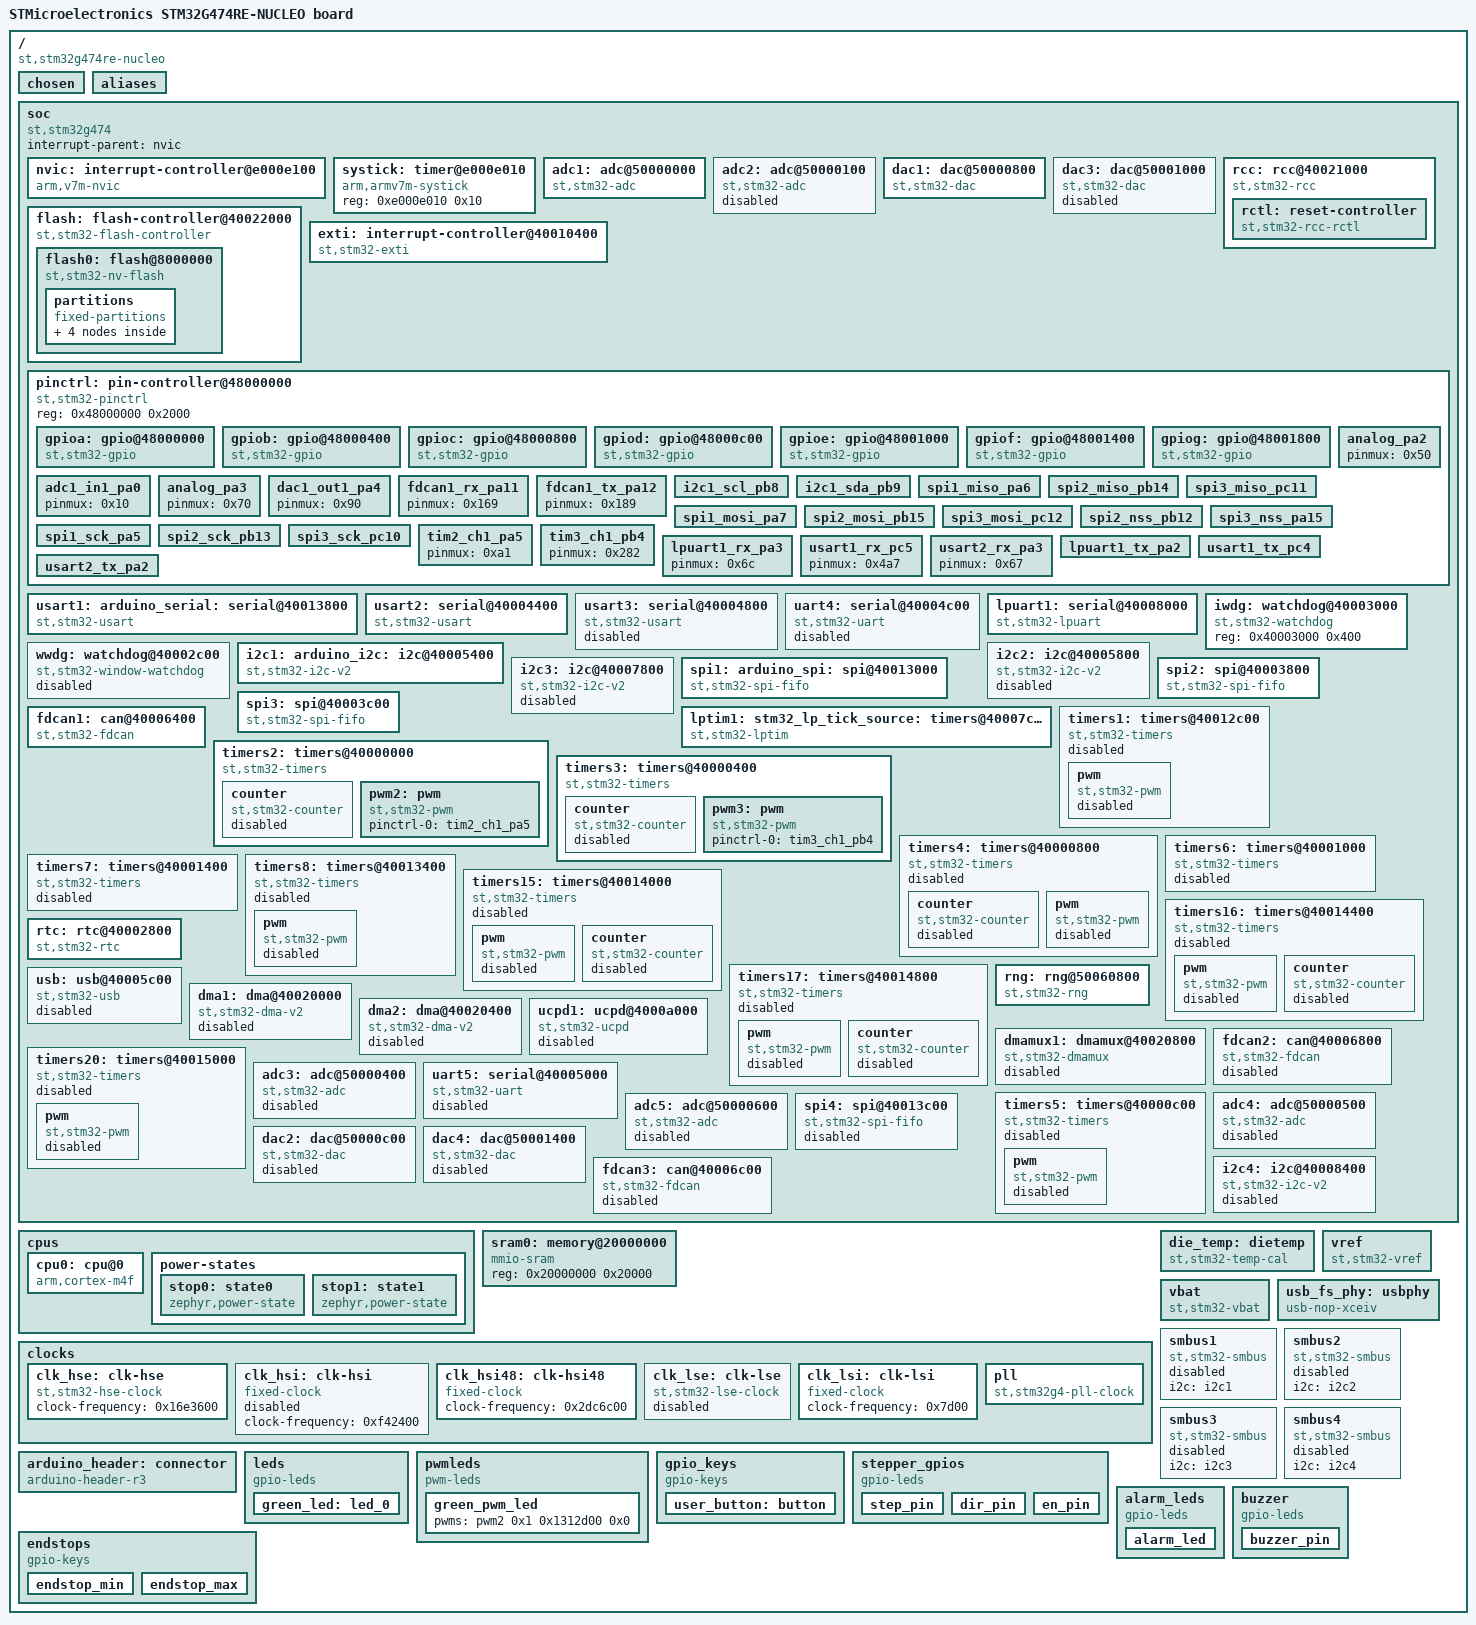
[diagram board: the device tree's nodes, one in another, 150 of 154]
/dts-v1/;

/ {
	#address-cells = < 0x1 >;
	#size-cells = < 0x1 >;
	model = "STMicroelectronics STM32G474RE-NUCLEO board";
	compatible = "st,stm32g474re-nucleo";
	chosen {
		zephyr,entropy = &rng;
		zephyr,flash-controller = &flash;
		zephyr,console = &lpuart1;
		zephyr,shell-uart = &lpuart1;
		zephyr,sram = &sram0;
		zephyr,flash = &flash0;
		zephyr,canbus = &fdcan1;
		zephyr,code-partition = &slot0_partition;
	};
	aliases {
		led0 = &green_led;
		mcuboot-led0 = &green_led;
		pwm-led0 = &green_pwm_led;
		sw0 = &user_button;
		watchdog0 = &iwdg;
		die-temp0 = &die_temp;
		volt-sensor0 = &vref;
		volt-sensor1 = &vbat;
	};
	soc {
		#address-cells = < 0x1 >;
		#size-cells = < 0x1 >;
		compatible = "st,stm32g474", "st,stm32g4", "simple-bus";
		interrupt-parent = < &nvic >;
		ranges;
		nvic: interrupt-controller@e000e100 {
			#address-cells = < 0x1 >;
			compatible = "arm,v7m-nvic";
			reg = < 0xe000e100 0xc00 >;
			interrupt-controller;
			#interrupt-cells = < 0x2 >;
			arm,num-irq-priority-bits = < 0x4 >;
			phandle = < 0x1 >;
		};
		systick: timer@e000e010 {
			compatible = "arm,armv7m-systick";
			reg = < 0xe000e010 0x10 >;
		};
		adc1: adc@50000000 {
			compatible = "st,stm32-adc";
			reg = < 0x50000000 0x100 >;
			clocks = < &rcc 0x4c 0x2000 >;
			interrupts = < 0x12 0x0 >;
			status = "okay";
			#io-channel-cells = < 0x1 >;
			resolutions = < 0x60630c 0x51630c 0x42630c 0x33630c >;
			sampling-times = < 0x3 0x7 0xd 0x19 0x30 0x5d 0xf8 0x281 >;
			st,adc-sequencer = < 0x1 >;
			pinctrl-0 = < &adc1_in1_pa0 >;
			pinctrl-names = "default";
			st,adc-clock-source = < 0x1 >;
			st,adc-prescaler = < 0x4 >;
			phandle = < 0x25 >;
		};
		adc2: adc@50000100 {
			compatible = "st,stm32-adc";
			reg = < 0x50000100 0x100 >;
			clocks = < &rcc 0x4c 0x2000 >;
			interrupts = < 0x12 0x0 >;
			status = "disabled";
			#io-channel-cells = < 0x1 >;
			resolutions = < 0x60630c 0x51630c 0x42630c 0x33630c >;
			sampling-times = < 0x3 0x7 0xd 0x19 0x30 0x5d 0xf8 0x281 >;
			st,adc-sequencer = < 0x1 >;
		};
		dac1: dac@50000800 {
			compatible = "st,stm32-dac";
			reg = < 0x50000800 0x400 >;
			clocks = < &rcc 0x4c 0x10000 >;
			status = "okay";
			#io-channel-cells = < 0x1 >;
			pinctrl-0 = < &dac1_out1_pa4 >;
			pinctrl-names = "default";
		};
		dac3: dac@50001000 {
			compatible = "st,stm32-dac";
			reg = < 0x50001000 0x400 >;
			clocks = < &rcc 0x4c 0x40000 >;
			status = "disabled";
			#io-channel-cells = < 0x1 >;
		};
		flash: flash-controller@40022000 {
			compatible = "st,stm32-flash-controller", "st,stm32g4-flash-controller";
			reg = < 0x40022000 0x400 >;
			interrupts = < 0x3 0x0 >;
			clocks = < &rcc 0x48 0x100 >;
			#address-cells = < 0x1 >;
			#size-cells = < 0x1 >;
			flash0: flash@8000000 {
				compatible = "st,stm32-nv-flash", "soc-nv-flash";
				write-block-size = < 0x8 >;
				erase-block-size = < 0x800 >;
				max-erase-time = < 0x19 >;
				reg = < 0x8000000 0x80000 >;
				partitions {
					compatible = "fixed-partitions";
					#address-cells = < 0x1 >;
					#size-cells = < 0x1 >;
					boot_partition: partition@0 {
						label = "mcuboot";
						reg = < 0x0 0x8800 >;
					};
					slot0_partition: partition@8800 {
						label = "image-0";
						reg = < 0x8800 0x3c000 >;
					};
					slot1_partition: partition@44800 {
						label = "image-1";
						reg = < 0x44800 0x3a800 >;
					};
					storage_partition: partition@7f000 {
						label = "storage";
						reg = < 0x7f000 0x1000 >;
					};
				};
			};
		};
		rcc: rcc@40021000 {
			compatible = "st,stm32-rcc";
			#clock-cells = < 0x2 >;
			reg = < 0x40021000 0x400 >;
			undershoot-prevention;
			clocks = < &pll >;
			clock-frequency = < 0xa21fe80 >;
			ahb-prescaler = < 0x1 >;
			apb1-prescaler = < 0x1 >;
			apb2-prescaler = < 0x1 >;
			phandle = < 0x2 >;
			rctl: reset-controller {
				compatible = "st,stm32-rcc-rctl";
				#reset-cells = < 0x1 >;
				phandle = < 0x6 >;
			};
		};
		exti: interrupt-controller@40010400 {
			compatible = "st,stm32-exti";
			interrupt-controller;
			#interrupt-cells = < 0x1 >;
			#address-cells = < 0x1 >;
			reg = < 0x40010400 0x400 >;
			num-lines = < 0x10 >;
			interrupts = < 0x6 0x0 >, < 0x7 0x0 >, < 0x8 0x0 >, < 0x9 0x0 >, < 0xa 0x0 >, < 0x17 0x0 >, < 0x28 0x0 >;
			interrupt-names = "line0", "line1", "line2-TSC", "line3", "line4", "line5-9", "line10-15";
			line-ranges = < 0x0 0x1 >, < 0x1 0x1 >, < 0x2 0x1 >, < 0x3 0x1 >, < 0x4 0x1 >, < 0x5 0x5 >, < 0xa 0x6 >;
		};
		pinctrl: pin-controller@48000000 {
			compatible = "st,stm32-pinctrl";
			#address-cells = < 0x1 >;
			#size-cells = < 0x1 >;
			reg = < 0x48000000 0x2000 >;
			gpioa: gpio@48000000 {
				compatible = "st,stm32-gpio";
				gpio-controller;
				#gpio-cells = < 0x2 >;
				reg = < 0x48000000 0x400 >;
				clocks = < &rcc 0x4c 0x1 >;
				phandle = < 0x2a >;
			};
			gpiob: gpio@48000400 {
				compatible = "st,stm32-gpio";
				gpio-controller;
				#gpio-cells = < 0x2 >;
				reg = < 0x48000400 0x400 >;
				clocks = < &rcc 0x4c 0x2 >;
				phandle = < 0x14 >;
			};
			gpioc: gpio@48000800 {
				compatible = "st,stm32-gpio";
				gpio-controller;
				#gpio-cells = < 0x2 >;
				reg = < 0x48000800 0x400 >;
				clocks = < &rcc 0x4c 0x4 >;
				phandle = < 0x2b >;
			};
			gpiod: gpio@48000c00 {
				compatible = "st,stm32-gpio";
				gpio-controller;
				#gpio-cells = < 0x2 >;
				reg = < 0x48000c00 0x400 >;
				clocks = < &rcc 0x4c 0x8 >;
			};
			gpioe: gpio@48001000 {
				compatible = "st,stm32-gpio";
				gpio-controller;
				#gpio-cells = < 0x2 >;
				reg = < 0x48001000 0x400 >;
				clocks = < &rcc 0x4c 0x10 >;
			};
			gpiof: gpio@48001400 {
				compatible = "st,stm32-gpio";
				gpio-controller;
				#gpio-cells = < 0x2 >;
				reg = < 0x48001400 0x400 >;
				clocks = < &rcc 0x4c 0x20 >;
			};
			gpiog: gpio@48001800 {
				compatible = "st,stm32-gpio";
				gpio-controller;
				#gpio-cells = < 0x2 >;
				reg = < 0x48001800 0x400 >;
				clocks = < &rcc 0x4c 0x40 >;
			};
			adc1_in1_pa0: adc1_in1_pa0 {
				pinmux = < 0x10 >;
				phandle = < 0x3 >;
			};
			analog_pa2: analog_pa2 {
				pinmux = < 0x50 >;
				phandle = < 0xd >;
			};
			analog_pa3: analog_pa3 {
				pinmux = < 0x70 >;
				phandle = < 0xe >;
			};
			dac1_out1_pa4: dac1_out1_pa4 {
				pinmux = < 0x90 >;
				phandle = < 0x4 >;
			};
			fdcan1_rx_pa11: fdcan1_rx_pa11 {
				pinmux = < 0x169 >;
				phandle = < 0x1d >;
			};
			fdcan1_tx_pa12: fdcan1_tx_pa12 {
				pinmux = < 0x189 >;
				phandle = < 0x1e >;
			};
			i2c1_scl_pb8: i2c1_scl_pb8 {
				pinmux = < 0x304 >;
				bias-pull-up;
				drive-open-drain;
				phandle = < 0xf >;
			};
			i2c1_sda_pb9: i2c1_sda_pb9 {
				pinmux = < 0x324 >;
				bias-pull-up;
				drive-open-drain;
				phandle = < 0x10 >;
			};
			spi1_miso_pa6: spi1_miso_pa6 {
				pinmux = < 0xc5 >;
				bias-pull-down;
				phandle = < 0x12 >;
			};
			spi2_miso_pb14: spi2_miso_pb14 {
				pinmux = < 0x3c5 >;
				bias-pull-down;
				phandle = < 0x17 >;
			};
			spi3_miso_pc11: spi3_miso_pc11 {
				pinmux = < 0x566 >;
				bias-pull-down;
				phandle = < 0x1b >;
			};
			spi1_mosi_pa7: spi1_mosi_pa7 {
				pinmux = < 0xe5 >;
				bias-pull-down;
				phandle = < 0x13 >;
			};
			spi2_mosi_pb15: spi2_mosi_pb15 {
				pinmux = < 0x3e5 >;
				bias-pull-down;
				phandle = < 0x18 >;
			};
			spi3_mosi_pc12: spi3_mosi_pc12 {
				pinmux = < 0x586 >;
				bias-pull-down;
				phandle = < 0x1c >;
			};
			spi2_nss_pb12: spi2_nss_pb12 {
				pinmux = < 0x385 >;
				bias-pull-up;
				phandle = < 0x15 >;
			};
			spi3_nss_pa15: spi3_nss_pa15 {
				pinmux = < 0x1e6 >;
				bias-pull-up;
				phandle = < 0x19 >;
			};
			spi1_sck_pa5: spi1_sck_pa5 {
				pinmux = < 0xa5 >;
				bias-pull-down;
				slew-rate = "very-high-speed";
				phandle = < 0x11 >;
			};
			spi2_sck_pb13: spi2_sck_pb13 {
				pinmux = < 0x3a5 >;
				bias-pull-down;
				slew-rate = "very-high-speed";
				phandle = < 0x16 >;
			};
			spi3_sck_pc10: spi3_sck_pc10 {
				pinmux = < 0x546 >;
				bias-pull-down;
				slew-rate = "very-high-speed";
				phandle = < 0x1a >;
			};
			tim2_ch1_pa5: tim2_ch1_pa5 {
				pinmux = < 0xa1 >;
				phandle = < 0x1f >;
			};
			tim3_ch1_pb4: tim3_ch1_pb4 {
				pinmux = < 0x282 >;
				phandle = < 0x20 >;
			};
			lpuart1_rx_pa3: lpuart1_rx_pa3 {
				pinmux = < 0x6c >;
				phandle = < 0xc >;
			};
			usart1_rx_pc5: usart1_rx_pc5 {
				pinmux = < 0x4a7 >;
				phandle = < 0x8 >;
			};
			usart2_rx_pa3: usart2_rx_pa3 {
				pinmux = < 0x67 >;
				phandle = < 0xa >;
			};
			lpuart1_tx_pa2: lpuart1_tx_pa2 {
				pinmux = < 0x4c >;
				bias-pull-up;
				phandle = < 0xb >;
			};
			usart1_tx_pc4: usart1_tx_pc4 {
				pinmux = < 0x487 >;
				bias-pull-up;
				phandle = < 0x7 >;
			};
			usart2_tx_pa2: usart2_tx_pa2 {
				pinmux = < 0x47 >;
				bias-pull-up;
				phandle = < 0x9 >;
			};
		};
		usart1: arduino_serial: serial@40013800 {
			compatible = "st,stm32-usart", "st,stm32-uart";
			reg = < 0x40013800 0x400 >;
			clocks = < &rcc 0x60 0x4000 >;
			resets = < &rctl 0x80e >;
			interrupts = < 0x25 0x0 >;
			status = "okay";
			pinctrl-0 = < &usart1_tx_pc4 &usart1_rx_pc5 >;
			pinctrl-names = "default";
			current-speed = < 0x1c200 >;
		};
		usart2: serial@40004400 {
			compatible = "st,stm32-usart", "st,stm32-uart";
			reg = < 0x40004400 0x400 >;
			clocks = < &rcc 0x58 0x20000 >;
			resets = < &rctl 0x711 >;
			interrupts = < 0x26 0x0 >;
			status = "okay";
			current-speed = < 0x1c200 >;
			pinctrl-0 = < &usart2_tx_pa2 &usart2_rx_pa3 >;
			pinctrl-names = "default";
		};
		usart3: serial@40004800 {
			compatible = "st,stm32-usart", "st,stm32-uart";
			reg = < 0x40004800 0x400 >;
			clocks = < &rcc 0x58 0x40000 >;
			resets = < &rctl 0x712 >;
			interrupts = < 0x27 0x0 >;
			status = "disabled";
		};
		uart4: serial@40004c00 {
			compatible = "st,stm32-uart";
			reg = < 0x40004c00 0x400 >;
			clocks = < &rcc 0x58 0x80000 >;
			resets = < &rctl 0x713 >;
			interrupts = < 0x34 0x0 >;
			status = "disabled";
		};
		lpuart1: serial@40008000 {
			compatible = "st,stm32-lpuart", "st,stm32-uart";
			reg = < 0x40008000 0x400 >;
			clocks = < &rcc 0x5c 0x1 >;
			resets = < &rctl 0x780 >;
			interrupts = < 0x5b 0x0 >;
			status = "okay";
			pinctrl-0 = < &lpuart1_tx_pa2 &lpuart1_rx_pa3 >;
			pinctrl-1 = < &analog_pa2 &analog_pa3 >;
			pinctrl-names = "default", "sleep";
			current-speed = < 0x1c200 >;
		};
		iwdg: watchdog@40003000 {
			compatible = "st,stm32-watchdog";
			reg = < 0x40003000 0x400 >;
			status = "okay";
		};
		wwdg: watchdog@40002c00 {
			compatible = "st,stm32-window-watchdog";
			reg = < 0x40002c00 0x400 >;
			clocks = < &rcc 0x58 0x800 >;
			interrupts = < 0x0 0x7 >;
			status = "disabled";
		};
		i2c1: arduino_i2c: i2c@40005400 {
			compatible = "st,stm32-i2c-v2";
			clock-frequency = < 0x186a0 >;
			#address-cells = < 0x1 >;
			#size-cells = < 0x0 >;
			reg = < 0x40005400 0x400 >;
			clocks = < &rcc 0x58 0x200000 >;
			interrupts = < 0x1f 0x0 >, < 0x20 0x0 >;
			interrupt-names = "event", "error";
			status = "okay";
			pinctrl-0 = < &i2c1_scl_pb8 &i2c1_sda_pb9 >;
			pinctrl-names = "default";
			phandle = < 0x26 >;
		};
		i2c2: i2c@40005800 {
			compatible = "st,stm32-i2c-v2";
			clock-frequency = < 0x186a0 >;
			#address-cells = < 0x1 >;
			#size-cells = < 0x0 >;
			reg = < 0x40005800 0x400 >;
			clocks = < &rcc 0x58 0x400000 >;
			interrupts = < 0x21 0x0 >, < 0x22 0x0 >;
			interrupt-names = "event", "error";
			status = "disabled";
			phandle = < 0x27 >;
		};
		i2c3: i2c@40007800 {
			compatible = "st,stm32-i2c-v2";
			clock-frequency = < 0x186a0 >;
			#address-cells = < 0x1 >;
			#size-cells = < 0x0 >;
			reg = < 0x40007800 0x400 >;
			clocks = < &rcc 0x58 0x40000000 >;
			interrupts = < 0x5c 0x0 >, < 0x5d 0x0 >;
			interrupt-names = "event", "error";
			status = "disabled";
			phandle = < 0x28 >;
		};
		spi1: arduino_spi: spi@40013000 {
			compatible = "st,stm32-spi-fifo", "st,stm32-spi";
			#address-cells = < 0x1 >;
			#size-cells = < 0x0 >;
			reg = < 0x40013000 0x400 >;
			interrupts = < 0x23 0x5 >;
			clocks = < &rcc 0x60 0x1000 >;
			status = "okay";
			pinctrl-0 = < &spi1_sck_pa5 &spi1_miso_pa6 &spi1_mosi_pa7 >;
			pinctrl-names = "default";
			cs-gpios = < &gpiob 0x6 0x11 >;
		};
		spi2: spi@40003800 {
			compatible = "st,stm32-spi-fifo", "st,stm32-spi";
			#address-cells = < 0x1 >;
			#size-cells = < 0x0 >;
			reg = < 0x40003800 0x400 >;
			clocks = < &rcc 0x58 0x4000 >;
			interrupts = < 0x24 0x5 >;
			status = "okay";
			pinctrl-0 = < &spi2_nss_pb12 &spi2_sck_pb13 &spi2_miso_pb14 &spi2_mosi_pb15 >;
			pinctrl-names = "default";
		};
		spi3: spi@40003c00 {
			compatible = "st,stm32-spi-fifo", "st,stm32-spi";
			#address-cells = < 0x1 >;
			#size-cells = < 0x0 >;
			reg = < 0x40003c00 0x400 >;
			clocks = < &rcc 0x58 0x8000 >;
			interrupts = < 0x33 0x5 >;
			status = "okay";
			pinctrl-0 = < &spi3_nss_pa15 &spi3_sck_pc10 &spi3_miso_pc11 &spi3_mosi_pc12 >;
			pinctrl-names = "default";
		};
		fdcan1: can@40006400 {
			compatible = "st,stm32-fdcan";
			reg = < 0x40006400 0x400 >, < 0x4000a400 0x350 >;
			reg-names = "m_can", "message_ram";
			interrupts = < 0x15 0x0 >, < 0x16 0x0 >;
			interrupt-names = "int0", "int1";
			clocks = < &rcc 0x58 0x2000000 >, < &rcc 0x6 0x7888 >;
			bosch,mram-cfg = < 0x0 0x1c 0x8 0x3 0x3 0x0 0x3 0x3 >;
			status = "okay";
			pinctrl-0 = < &fdcan1_rx_pa11 &fdcan1_tx_pa12 >;
			pinctrl-names = "default";
		};
		lptim1: stm32_lp_tick_source: timers@40007c00 {
			compatible = "st,stm32-lptim";
			clocks = < &rcc 0x58 0x80000000 >, < &rcc 0x3 0x17288 >;
			#address-cells = < 0x1 >;
			#size-cells = < 0x0 >;
			reg = < 0x40007c00 0x400 >;
			interrupts = < 0x31 0x1 >;
			interrupt-names = "wakeup";
			status = "okay";
		};
		timers1: timers@40012c00 {
			compatible = "st,stm32-timers";
			reg = < 0x40012c00 0x400 >;
			clocks = < &rcc 0x60 0x800 >;
			resets = < &rctl 0x80b >;
			interrupts = < 0x18 0x0 >, < 0x19 0x0 >, < 0x1a 0x0 >, < 0x1b 0x0 >;
			interrupt-names = "brk", "up", "trgcom", "cc";
			st,prescaler = < 0x0 >;
			status = "disabled";
			pwm {
				compatible = "st,stm32-pwm";
				status = "disabled";
				#pwm-cells = < 0x3 >;
			};
		};
		timers2: timers@40000000 {
			compatible = "st,stm32-timers";
			reg = < 0x40000000 0x400 >;
			clocks = < &rcc 0x58 0x1 >;
			resets = < &rctl 0x700 >;
			interrupts = < 0x1c 0x0 >;
			interrupt-names = "global";
			st,prescaler = < 0x0 >;
			status = "okay";
			counter {
				compatible = "st,stm32-counter";
				status = "disabled";
			};
			pwm2: pwm {
				compatible = "st,stm32-pwm";
				status = "okay";
				#pwm-cells = < 0x3 >;
				pinctrl-0 = < &tim2_ch1_pa5 >;
				pinctrl-names = "default";
				phandle = < 0x2c >;
			};
		};
		timers3: timers@40000400 {
			compatible = "st,stm32-timers";
			reg = < 0x40000400 0x400 >;
			clocks = < &rcc 0x58 0x2 >;
			resets = < &rctl 0x701 >;
			interrupts = < 0x1d 0x0 >;
			interrupt-names = "global";
			st,prescaler = < 0x2710 >;
			status = "okay";
			counter {
				compatible = "st,stm32-counter";
				status = "disabled";
			};
			pwm3: pwm {
				compatible = "st,stm32-pwm";
				status = "okay";
				#pwm-cells = < 0x3 >;
				pinctrl-0 = < &tim3_ch1_pb4 >;
				pinctrl-names = "default";
			};
		};
		timers4: timers@40000800 {
			compatible = "st,stm32-timers";
			reg = < 0x40000800 0x400 >;
			clocks = < &rcc 0x58 0x4 >;
			resets = < &rctl 0x702 >;
			interrupts = < 0x1e 0x0 >;
			interrupt-names = "global";
			st,prescaler = < 0x0 >;
			status = "disabled";
			counter {
				compatible = "st,stm32-counter";
				status = "disabled";
			};
			pwm {
				compatible = "st,stm32-pwm";
				status = "disabled";
				#pwm-cells = < 0x3 >;
			};
		};
		timers6: timers@40001000 {
			compatible = "st,stm32-timers";
			reg = < 0x40001000 0x400 >;
			clocks = < &rcc 0x58 0x10 >;
			resets = < &rctl 0x704 >;
			interrupts = < 0x36 0x0 >;
			interrupt-names = "global";
			st,prescaler = < 0x0 >;
			status = "disabled";
		};
		timers7: timers@40001400 {
			compatible = "st,stm32-timers";
			reg = < 0x40001400 0x400 >;
			clocks = < &rcc 0x58 0x20 >;
			resets = < &rctl 0x705 >;
			interrupts = < 0x37 0x0 >;
			interrupt-names = "global";
			st,prescaler = < 0x0 >;
			status = "disabled";
		};
		timers8: timers@40013400 {
			compatible = "st,stm32-timers";
			reg = < 0x40013400 0x400 >;
			clocks = < &rcc 0x60 0x2000 >;
			resets = < &rctl 0x80d >;
			interrupts = < 0x2b 0x0 >, < 0x2c 0x0 >, < 0x2d 0x0 >, < 0x2e 0x0 >;
			interrupt-names = "brk", "up", "trgcom", "cc";
			st,prescaler = < 0x0 >;
			status = "disabled";
			pwm {
				compatible = "st,stm32-pwm";
				status = "disabled";
				#pwm-cells = < 0x3 >;
			};
		};
		timers15: timers@40014000 {
			compatible = "st,stm32-timers";
			reg = < 0x40014000 0x400 >;
			clocks = < &rcc 0x60 0x10000 >;
			resets = < &rctl 0x810 >;
			interrupts = < 0x18 0x0 >;
			interrupt-names = "global";
			st,prescaler = < 0x0 >;
			status = "disabled";
			pwm {
				compatible = "st,stm32-pwm";
				status = "disabled";
				#pwm-cells = < 0x3 >;
			};
			counter {
				compatible = "st,stm32-counter";
				status = "disabled";
			};
		};
		timers16: timers@40014400 {
			compatible = "st,stm32-timers";
			reg = < 0x40014400 0x400 >;
			clocks = < &rcc 0x60 0x20000 >;
			resets = < &rctl 0x811 >;
			interrupts = < 0x19 0x0 >;
			interrupt-names = "global";
			st,prescaler = < 0x0 >;
			status = "disabled";
			pwm {
				compatible = "st,stm32-pwm";
				status = "disabled";
				#pwm-cells = < 0x3 >;
			};
			counter {
				compatible = "st,stm32-counter";
				status = "disabled";
			};
		};
		timers17: timers@40014800 {
			compatible = "st,stm32-timers";
			reg = < 0x40014800 0x400 >;
			clocks = < &rcc 0x60 0x40000 >;
			resets = < &rctl 0x812 >;
			interrupts = < 0x1a 0x0 >;
			interrupt-names = "global";
			st,prescaler = < 0x0 >;
			status = "disabled";
			pwm {
				compatible = "st,stm32-pwm";
				status = "disabled";
				#pwm-cells = < 0x3 >;
			};
			counter {
				compatible = "st,stm32-counter";
				status = "disabled";
			};
		};
		rtc: rtc@40002800 {
			compatible = "st,stm32-rtc";
			reg = < 0x40002800 0x400 >;
			interrupts = < 0x29 0x0 >;
			clocks = < &rcc 0x58 0x400 >, < &rcc 0x3 0x26890 >;
			prescaler = < 0x8000 >;
			alarms-count = < 0x2 >;
			alrm-exti-line = < 0x11 >;
			status = "okay";
		};
		rng: rng@50060800 {
			compatible = "st,stm32-rng";
			reg = < 0x50060800 0x400 >;
			interrupts = < 0x5a 0x0 >;
			clocks = < &rcc 0x4c 0x4000000 >;
			status = "okay";
		};
		usb: usb@40005c00 {
			compatible = "st,stm32-usb";
			reg = < 0x40005c00 0x400 >;
			interrupts = < 0x14 0x0 >, < 0x13 0x0 >;
			interrupt-names = "usb", "usbhp";
			num-bidir-endpoints = < 0x8 >;
			ram-size = < 0x400 >;
			phys = < &usb_fs_phy >;
			clocks = < &rcc 0x58 0x800000 >, < &rcc 0x5 0x7a88 >;
			status = "disabled";
		};
		dma1: dma@40020000 {
			compatible = "st,stm32-dma-v2";
			#dma-cells = < 0x3 >;
			reg = < 0x40020000 0x400 >;
			clocks = < &rcc 0x48 0x1 >;
			dma-offset = < 0x0 >;
			status = "disabled";
			interrupts = < 0xb 0x0 0xc 0x0 0xd 0x0 0xe 0x0 0xf 0x0 0x10 0x0 0x11 0x0 0x60 0x0 >;
			dma-requests = < 0x8 >;
		};
		dma2: dma@40020400 {
			compatible = "st,stm32-dma-v2";
			#dma-cells = < 0x3 >;
			reg = < 0x40020400 0x400 >;
			clocks = < &rcc 0x48 0x2 >;
			status = "disabled";
			interrupts = < 0x38 0x0 0x39 0x0 0x3a 0x0 0x3b 0x0 0x3c 0x0 0x61 0x0 0x62 0x0 0x63 0x0 >;
			dma-requests = < 0x8 >;
			dma-offset = < 0x8 >;
		};
		dmamux1: dmamux@40020800 {
			compatible = "st,stm32-dmamux";
			#dma-cells = < 0x3 >;
			reg = < 0x40020800 0x400 >;
			interrupts = < 0x5e 0x0 >;
			clocks = < &rcc 0x48 0x4 >;
			dma-generators = < 0x4 >;
			dma-requests = < 0x6f >;
			status = "disabled";
			dma-channels = < 0x10 >;
		};
		ucpd1: ucpd@4000a000 {
			compatible = "st,stm32-ucpd";
			reg = < 0x4000a000 0x400 >;
			clocks = < &rcc 0x58 0x10 >;
			interrupts = < 0x3f 0x0 >;
			status = "disabled";
		};
		fdcan2: can@40006800 {
			compatible = "st,stm32-fdcan";
			reg = < 0x40006800 0x400 >, < 0x4000a400 0x6a0 >;
			reg-names = "m_can", "message_ram";
			interrupts = < 0x56 0x0 >, < 0x57 0x0 >;
			interrupt-names = "int0", "int1";
			clocks = < &rcc 0x58 0x2000000 >;
			bosch,mram-cfg = < 0x350 0x1c 0x8 0x3 0x3 0x0 0x3 0x3 >;
			status = "disabled";
		};
		timers20: timers@40015000 {
			compatible = "st,stm32-timers";
			reg = < 0x40015000 0x400 >;
			clocks = < &rcc 0x60 0x100000 >;
			resets = < &rctl 0x814 >;
			interrupts = < 0x4d 0x0 >, < 0x4e 0x0 >, < 0x4f 0x0 >, < 0x50 0x0 >;
			interrupt-names = "brk", "up", "trgcom", "cc";
			st,prescaler = < 0x0 >;
			status = "disabled";
			pwm {
				compatible = "st,stm32-pwm";
				status = "disabled";
				#pwm-cells = < 0x3 >;
			};
		};
		adc3: adc@50000400 {
			compatible = "st,stm32-adc";
			reg = < 0x50000400 0x100 >;
			clocks = < &rcc 0x4c 0x4000 >;
			interrupts = < 0x2f 0x0 >;
			status = "disabled";
			#io-channel-cells = < 0x1 >;
			resolutions = < 0x60630c 0x51630c 0x42630c 0x33630c >;
			sampling-times = < 0x3 0x7 0xd 0x19 0x30 0x5d 0xf8 0x281 >;
			st,adc-sequencer = < 0x1 >;
		};
		uart5: serial@40005000 {
			compatible = "st,stm32-uart";
			reg = < 0x40005000 0x400 >;
			clocks = < &rcc 0x58 0x100000 >;
			resets = < &rctl 0x714 >;
			interrupts = < 0x35 0x0 >;
			status = "disabled";
		};
		timers5: timers@40000c00 {
			compatible = "st,stm32-timers";
			reg = < 0x40000c00 0x400 >;
			clocks = < &rcc 0x58 0x8 >;
			resets = < &rctl 0x703 >;
			interrupts = < 0x32 0x0 >;
			interrupt-names = "global";
			st,prescaler = < 0x0 >;
			status = "disabled";
			pwm {
				compatible = "st,stm32-pwm";
				status = "disabled";
				#pwm-cells = < 0x3 >;
			};
		};
		adc4: adc@50000500 {
			compatible = "st,stm32-adc";
			reg = < 0x50000500 0x100 >;
			clocks = < &rcc 0x4c 0x4000 >;
			interrupts = < 0x3d 0x0 >;
			status = "disabled";
			#io-channel-cells = < 0x1 >;
			resolutions = < 0x60630c 0x51630c 0x42630c 0x33630c >;
			sampling-times = < 0x3 0x7 0xd 0x19 0x30 0x5d 0xf8 0x281 >;
			st,adc-sequencer = < 0x1 >;
		};
		adc5: adc@50000600 {
			compatible = "st,stm32-adc";
			reg = < 0x50000600 0x100 >;
			clocks = < &rcc 0x4c 0x4000 >;
			interrupts = < 0x3e 0x0 >;
			status = "disabled";
			#io-channel-cells = < 0x1 >;
			resolutions = < 0x60630c 0x51630c 0x42630c 0x33630c >;
			sampling-times = < 0x3 0x7 0xd 0x19 0x30 0x5d 0xf8 0x281 >;
			st,adc-sequencer = < 0x1 >;
		};
		spi4: spi@40013c00 {
			compatible = "st,stm32-spi-fifo", "st,stm32-spi";
			#address-cells = < 0x1 >;
			#size-cells = < 0x0 >;
			reg = < 0x40013c00 0x400 >;
			clocks = < &rcc 0x60 0x8000 >;
			interrupts = < 0x54 0x5 >;
			status = "disabled";
		};
		dac2: dac@50000c00 {
			compatible = "st,stm32-dac";
			reg = < 0x50000c00 0x400 >;
			clocks = < &rcc 0x4c 0x20000 >;
			status = "disabled";
			#io-channel-cells = < 0x1 >;
		};
		dac4: dac@50001400 {
			compatible = "st,stm32-dac";
			reg = < 0x50001400 0x400 >;
			clocks = < &rcc 0x4c 0x80000 >;
			status = "disabled";
			#io-channel-cells = < 0x1 >;
		};
		i2c4: i2c@40008400 {
			compatible = "st,stm32-i2c-v2";
			clock-frequency = < 0x186a0 >;
			#address-cells = < 0x1 >;
			#size-cells = < 0x0 >;
			reg = < 0x40008400 0x400 >;
			clocks = < &rcc 0x5c 0x2 >;
			interrupts = < 0x52 0x0 >, < 0x53 0x0 >;
			interrupt-names = "event", "error";
			status = "disabled";
			phandle = < 0x29 >;
		};
		fdcan3: can@40006c00 {
			compatible = "st,stm32-fdcan";
			reg = < 0x40006c00 0x400 >, < 0x4000a400 0x9f0 >;
			reg-names = "m_can", "message_ram";
			interrupts = < 0x58 0x0 >, < 0x59 0x0 >;
			interrupt-names = "int0", "int1";
			clocks = < &rcc 0x58 0x2000000 >;
			bosch,mram-cfg = < 0x6a0 0x1c 0x8 0x3 0x3 0x0 0x3 0x3 >;
			status = "disabled";
		};
	};
	cpus {
		#address-cells = < 0x1 >;
		#size-cells = < 0x0 >;
		cpu0: cpu@0 {
			device_type = "cpu";
			compatible = "arm,cortex-m4f";
			reg = < 0x0 >;
			cpu-power-states = < &stop0 &stop1 >;
		};
		power-states {
			stop0: state0 {
				compatible = "zephyr,power-state";
				power-state-name = "suspend-to-idle";
				substate-id = < 0x1 >;
				min-residency-us = < 0x14 >;
				phandle = < 0x22 >;
			};
			stop1: state1 {
				compatible = "zephyr,power-state";
				power-state-name = "suspend-to-idle";
				substate-id = < 0x2 >;
				min-residency-us = < 0x64 >;
				phandle = < 0x23 >;
			};
		};
	};
	sram0: memory@20000000 {
		compatible = "mmio-sram";
		reg = < 0x20000000 0x20000 >;
	};
	clocks {
		clk_hse: clk-hse {
			#clock-cells = < 0x0 >;
			compatible = "st,stm32-hse-clock";
			status = "okay";
			clock-frequency = < 0x16e3600 >;
			phandle = < 0x24 >;
		};
		clk_hsi: clk-hsi {
			#clock-cells = < 0x0 >;
			compatible = "fixed-clock";
			clock-frequency = < 0xf42400 >;
			status = "disabled";
		};
		clk_hsi48: clk-hsi48 {
			#clock-cells = < 0x0 >;
			compatible = "fixed-clock";
			clock-frequency = < 0x2dc6c00 >;
			status = "okay";
		};
		clk_lse: clk-lse {
			#clock-cells = < 0x0 >;
			compatible = "st,stm32-lse-clock";
			clock-frequency = < 0x8000 >;
			driving-capability = < 0x0 >;
			status = "disabled";
		};
		clk_lsi: clk-lsi {
			#clock-cells = < 0x0 >;
			compatible = "fixed-clock";
			clock-frequency = < 0x7d00 >;
			status = "okay";
		};
		pll: pll {
			#clock-cells = < 0x0 >;
			compatible = "st,stm32g4-pll-clock";
			status = "okay";
			div-m = < 0x6 >;
			mul-n = < 0x55 >;
			div-p = < 0x7 >;
			div-q = < 0x2 >;
			div-r = < 0x2 >;
			clocks = < &clk_hse >;
			phandle = < 0x5 >;
		};
	};
	die_temp: dietemp {
		compatible = "st,stm32-temp-cal";
		ts-cal1-addr = < 0x1fff75a8 >;
		ts-cal2-addr = < 0x1fff75ca >;
		ts-cal1-temp = < 0x1e >;
		ts-cal2-temp = < 0x82 >;
		ts-cal-vrefanalog = < 0xbb8 >;
		io-channels = < &adc1 0x10 >;
		status = "okay";
	};
	vref: vref {
		compatible = "st,stm32-vref";
		vrefint-cal-addr = < 0x1fff75aa >;
		vrefint-cal-mv = < 0xbb8 >;
		io-channels = < &adc1 0x12 >;
		status = "okay";
	};
	vbat: vbat {
		compatible = "st,stm32-vbat";
		ratio = < 0x3 >;
		io-channels = < &adc1 0x11 >;
		status = "okay";
	};
	usb_fs_phy: usbphy {
		compatible = "usb-nop-xceiv";
		#phy-cells = < 0x0 >;
		phandle = < 0x21 >;
	};
	smbus1: smbus1 {
		compatible = "st,stm32-smbus";
		#address-cells = < 0x1 >;
		#size-cells = < 0x0 >;
		i2c = < &i2c1 >;
		status = "disabled";
	};
	smbus2: smbus2 {
		compatible = "st,stm32-smbus";
		#address-cells = < 0x1 >;
		#size-cells = < 0x0 >;
		i2c = < &i2c2 >;
		status = "disabled";
	};
	smbus3: smbus3 {
		compatible = "st,stm32-smbus";
		#address-cells = < 0x1 >;
		#size-cells = < 0x0 >;
		i2c = < &i2c3 >;
		status = "disabled";
	};
	smbus4: smbus4 {
		compatible = "st,stm32-smbus";
		#address-cells = < 0x1 >;
		#size-cells = < 0x0 >;
		i2c = < &i2c4 >;
		status = "disabled";
	};
	arduino_header: connector {
		compatible = "arduino-header-r3";
		#gpio-cells = < 0x2 >;
		gpio-map-mask = < 0xffffffff 0xffffffc0 >;
		gpio-map-pass-thru = < 0x0 0x3f >;
		gpio-map = < 0x0 0x0 &gpioa 0x0 0x0 >, < 0x1 0x0 &gpioa 0x1 0x0 >, < 0x2 0x0 &gpioa 0x4 0x0 >, < 0x3 0x0 &gpiob 0x0 0x0 >, < 0x4 0x0 &gpioc 0x1 0x0 >, < 0x5 0x0 &gpioc 0x0 0x0 >, < 0x6 0x0 &gpioc 0x5 0x0 >, < 0x7 0x0 &gpioc 0x4 0x0 >, < 0x8 0x0 &gpioa 0xa 0x0 >, < 0x9 0x0 &gpiob 0x3 0x0 >, < 0xa 0x0 &gpiob 0x5 0x0 >, < 0xb 0x0 &gpiob 0x4 0x0 >, < 0xc 0x0 &gpiob 0xa 0x0 >, < 0xd 0x0 &gpioa 0x8 0x0 >, < 0xe 0x0 &gpioa 0x9 0x0 >, < 0xf 0x0 &gpioc 0x7 0x0 >, < 0x10 0x0 &gpiob 0x6 0x0 >, < 0x11 0x0 &gpioa 0x7 0x0 >, < 0x12 0x0 &gpioa 0x6 0x0 >, < 0x13 0x0 &gpioa 0x5 0x0 >, < 0x14 0x0 &gpiob 0x9 0x0 >, < 0x15 0x0 &gpiob 0x8 0x0 >;
	};
	leds: leds {
		compatible = "gpio-leds";
		green_led: led_0 {
			gpios = < &gpioa 0x5 0x0 >;
			label = "User LD2";
		};
	};
	pwmleds {
		compatible = "pwm-leds";
		green_pwm_led: green_pwm_led {
			pwms = < &pwm2 0x1 0x1312d00 0x0 >;
		};
	};
	gpio_keys {
		compatible = "gpio-keys";
		user_button: button {
			label = "User";
			gpios = < &gpioc 0xd 0x1 >;
			zephyr,code = < 0xb >;
		};
	};
	stepper_gpios {
		compatible = "gpio-leds";
		step_pin: step_pin {
			gpios = < &gpiob 0x0 0x0 >;
			label = "STEPPER_STEP";
		};
		dir_pin: dir_pin {
			gpios = < &gpiob 0x1 0x0 >;
			label = "STEPPER_DIR";
		};
		en_pin: en_pin {
			gpios = < &gpiob 0x2 0x1 >;
			label = "STEPPER_EN";
		};
	};
	alarm_leds {
		compatible = "gpio-leds";
		alarm_led: alarm_led {
			gpios = < &gpioc 0xd 0x0 >;
			label = "ALARM_LED";
		};
	};
	buzzer {
		compatible = "gpio-leds";
		buzzer_pin: buzzer_pin {
			gpios = < &gpioa 0xa 0x0 >;
			label = "BUZZER";
		};
	};
	endstops {
		compatible = "gpio-keys";
		endstop_min: endstop_min {
			gpios = < &gpioa 0x8 0x11 >;
			label = "ENDSTOP_MIN";
		};
		endstop_max: endstop_max {
			gpios = < &gpioa 0x9 0x11 >;
			label = "ENDSTOP_MAX";
		};
	};
};
